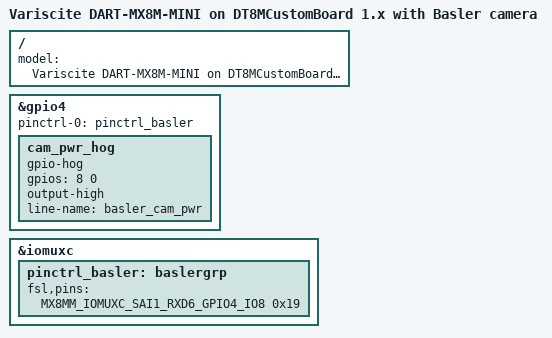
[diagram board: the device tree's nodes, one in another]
/*
 *  Devicetree for a Basler camera on Variscite DART-MX8M-MINI
 *
 *  Created by Hauke Wulff on 23.07.19.
 *  Copyright (c) 2019 Basler AG. All rights reserved.
 *  Copyright 2020-2021 Variscte Ltd.
 *
 */

#include "imx8mm-var-dart-dt8mcustomboard-legacy.dts"
#include "imx8mm-var-dart-dt8mcustomboard-basler.dtsi"

/ {
	model = "Variscite DART-MX8M-MINI on DT8MCustomBoard 1.x with Basler camera";
};

&gpio4 {
	pinctrl-names = "default";
	pinctrl-0 = <&pinctrl_basler>;

	cam_pwr_hog {
		gpio-hog;
		gpios = <8 0>;
		output-high;
		line-name = "basler_cam_pwr";
	};
};

&iomuxc {
	pinctrl_basler: baslergrp {
		fsl,pins = <
			MX8MM_IOMUXC_SAI1_RXD6_GPIO4_IO8      0x19
		>;
	};
};
